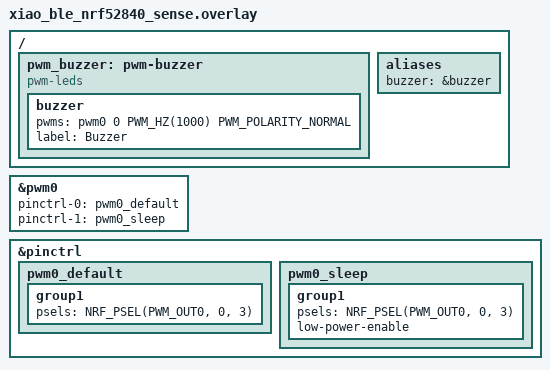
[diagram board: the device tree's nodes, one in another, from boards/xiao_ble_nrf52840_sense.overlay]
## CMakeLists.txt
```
# SPDX-License-Identifier: Apache-2.0

cmake_minimum_required(VERSION 3.20.0)
find_package(Zephyr REQUIRED HINTS $ENV{ZEPHYR_BASE})
project(project_base_node)

target_include_directories(app PRIVATE include)

target_sources(app PRIVATE src/main.c src/nus_central.c src/json_serial.c src/watchdog.c src/buzzer.c src/air_quality.c src/kalman.c src/node_buffer.c)
```

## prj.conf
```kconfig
CONFIG_SHELL=y
CONFIG_PRINTK=y
CONFIG_UART_CONSOLE=y

# Bluetooth core
CONFIG_BT=y
CONFIG_BT_CENTRAL=y
CONFIG_BT_GATT_CLIENT=y
CONFIG_BT_SMP=y
CONFIG_BT_MAX_CONN=1
CONFIG_BT_OBSERVER=y

# Data Length Extension and MTU
CONFIG_BT_USER_DATA_LEN_UPDATE=y
CONFIG_BT_CTLR_DATA_LENGTH_MAX=251
CONFIG_BT_BUF_ACL_RX_SIZE=251
CONFIG_BT_BUF_ACL_TX_SIZE=251
CONFIG_BT_L2CAP_TX_MTU=247

# Logging
CONFIG_LOG=y
CONFIG_LOG_DEFAULT_LEVEL=3

CONFIG_JSON_LIBRARY=y

CONFIG_WATCHDOG=y

CONFIG_PWM=y
CONFIG_PWM_LOG_LEVEL_DBG=y

CONFIG_FPU=y
CONFIG_FPU_SHARING=y
CONFIG_CBPRINTF_FP_SUPPORT=y
```

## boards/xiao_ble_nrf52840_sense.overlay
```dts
/ {
    pwm_buzzer: pwm-buzzer {
        compatible = "pwm-leds";
        buzzer: buzzer {
            pwms = <&pwm0 0 PWM_HZ(1000) PWM_POLARITY_NORMAL>;
            label = "Buzzer";
        };
    };

    aliases {
        buzzer = &buzzer;
    };
};

&pwm0 {
    status = "okay";
    pinctrl-0 = <&pwm0_default>;
    pinctrl-1 = <&pwm0_sleep>;
    pinctrl-names = "default", "sleep";
};

&pinctrl {
    pwm0_default: pwm0_default {
        group1 {
            psels = <NRF_PSEL(PWM_OUT0, 0, 3)>;
        };
    };

    pwm0_sleep: pwm0_sleep {
        group1 {
            psels = <NRF_PSEL(PWM_OUT0, 0, 3)>;
            low-power-enable;
        };
    };
};
```

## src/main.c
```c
#include <zephyr/kernel.h>
#include <zephyr/logging/log.h>
#include <zephyr/shell/shell.h>

#include "nus_central.h"
#include "watchdog.h"
#include "air_quality.h"
#include "buzzer.h"
#include "node_buffer.h"

LOG_MODULE_REGISTER(main, LOG_LEVEL_INF);

#define CMD_MEASURE 0x01
#define CMD_SLEEP   0x02

#define WDT_FEED_STACK  512
#define WDT_FEED_PERIOD_MS 2000  

K_THREAD_STACK_DEFINE(wdt_feed_stack, WDT_FEED_STACK);
static struct k_thread wdt_feed_thread_data;

static int cmd_wake(const struct shell *sh, size_t argc, char **argv)
{
    ARG_UNUSED(argc);
    ARG_UNUSED(argv);

    if (!nus_central_is_connected()) {
        shell_error(sh, "Not connected to mobile_node");
        return -ENOTCONN;
    }

    int err = nus_send_command(CMD_MEASURE);
    if (err) {
        shell_error(sh, "Failed to send CMD_MEASURE (err %d)", err);
        return err;
    }

    return 0;
}

static int cmd_sleep(const struct shell *sh, size_t argc, char **argv)
{
    ARG_UNUSED(argc);
    ARG_UNUSED(argv);

    if (!nus_central_is_connected()) {
        shell_error(sh, "Not connected to mobile_node");
        return -ENOTCONN;
    }

    int err = nus_send_command(CMD_SLEEP);
    if (err) {
        shell_error(sh, "Failed to send CMD_SLEEP (err %d)", err);
        return err;
    }

    shell_print(sh, "CMD_SLEEP sent to mobile_node");
    buzzer_stop();
    air_quality_reset();
    nus_central_reset_classification();

    return 0;
}

SHELL_CMD_REGISTER(wake,  NULL, "Send CMD_MEASURE to sensor mesh", cmd_wake);
SHELL_CMD_REGISTER(sleep, NULL, "Send CMD_SLEEP to sensor mesh",   cmd_sleep);

static void wdt_feed_thread(void *p1, void *p2, void *p3)
{
    ARG_UNUSED(p1);
    ARG_UNUSED(p2);
    ARG_UNUSED(p3);

    while (1) {
        watchdog_feed();
        k_sleep(K_MSEC(WDT_FEED_PERIOD_MS));
    }
}

int main(void)
{
    watchdog_init();

    k_thread_create(&wdt_feed_thread_data, wdt_feed_stack,
                    WDT_FEED_STACK,
                    wdt_feed_thread, NULL, NULL, NULL,
                    7, 0, K_NO_WAIT);
    k_thread_name_set(&wdt_feed_thread_data, "wdt_feed");

    node_buffer_init();
    air_quality_init();
    buzzer_init();

    int err = nus_central_init();
    if (err) {
        LOG_ERR("NUS central init failed (err %d)", err);
        return err;
    }

    return 0;
}
```

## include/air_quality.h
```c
#ifndef AIR_QUALITY_H
#define AIR_QUALITY_H

#include <stdint.h>

typedef enum {
    AQ_GOOD,
    AQ_WARNING,
    AQ_POOR
} air_quality_t;


void air_quality_init(void);
void air_quality_update(uint16_t eco2_ppm, uint16_t tvoc_ppb);
void air_quality_reset(void);
air_quality_t air_quality_get_eco2(void);
air_quality_t air_quality_get_tvoc(void);
float air_quality_get_eco2_estimate(void);
float air_quality_get_tvoc_estimate(void);

#endif /* AIR_QUALITY_H */
```

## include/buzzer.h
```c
#ifndef BUZZER_H
#define BUZZER_H

int buzzer_init(void);
void buzzer_warning(void);
void buzzer_poor(void);
void buzzer_stop(void);

#endif /* BUZZER_H */
```

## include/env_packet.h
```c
#ifndef ENV_PACKET_H
#define ENV_PACKET_H

#include <stdint.h>

#define ENV_NODE_NAME_LEN 8

struct env_record {
    char     node_id[ENV_NODE_NAME_LEN];  
    uint32_t timestamp_ms;                 
    int16_t  temp_centi_c;                 
    uint16_t hum_centi_rh;                
    uint16_t eco2_ppm;                     
    uint16_t tvoc_ppb;                     
};

#endif /* ENV_PACKET_H */
```

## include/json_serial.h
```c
#ifndef JSON_SERIAL_H
#define JSON_SERIAL_H

#include "env_packet.h"

void json_serial_send(const struct env_record *rec);
void json_serial_send_kalman(void);

#endif /* JSON_SERIAL_H */
```

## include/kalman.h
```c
#ifndef KALMAN_H
#define KALMAN_H

#include <stdint.h>

struct kalman_filter {
    float x; 
    float p;  
    float q;  
    float r; 
};

void kalman_init(struct kalman_filter *kf, float q, float r, float initial_x);
float kalman_update(struct kalman_filter *kf, float measurement);

#endif /* KALMAN_H */
```

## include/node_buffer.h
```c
#ifndef NODE_BUFFER_H
#define NODE_BUFFER_H

#include "env_packet.h"
#include <stdbool.h>

#define NODE_BUFFER_MAX 8

void node_buffer_init(void);
void node_buffer_add(const struct env_record *rec);
int node_buffer_count(void);
const struct env_record *node_buffer_get(int index);
void node_buffer_clear(void);

#endif /* NODE_BUFFER_H */
```

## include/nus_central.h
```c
#ifndef NUS_CENTRAL_H
#define NUS_CENTRAL_H

#include <stdint.h>
#include <stdbool.h>


int nus_central_init(void);
int nus_send_command(uint8_t cmd);
bool nus_central_is_connected(void);
// Resets air_quality classification
void nus_central_reset_classification(void);

#endif /* NUS_CENTRAL_H */
```

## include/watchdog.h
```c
#ifndef WATCHDOG_H
#define WATCHDOG_H

int watchdog_init(void);
void watchdog_feed(void);

#endif /* WATCHDOG_H */
```

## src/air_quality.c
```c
/*
 * Black-Valetudo - Base Node
 * Air quality classification using Kalman filter
 */

#include "air_quality.h"
#include "kalman.h"

#include <zephyr/kernel.h>
#include <zephyr/logging/log.h>

LOG_MODULE_REGISTER(air_quality, LOG_LEVEL_INF);

/* ==========================================================================
 * Kalman filter tuning parameters
 *
 * Q — process noise: how much we expect the true value to drift per update
 *     larger Q = trust measurements more, filter responds faster
 *
 * R — measurement noise: how noisy the sensor readings are
 *     larger R = trust measurements less, filter responds slower
 * ========================================================================== */

#define ECO2_Q          5.0f /* increased from 1.0f to 5.0f to track changes faster*/
#define ECO2_R          10.0f
#define ECO2_INITIAL    400.0f   /* typical outdoor CO2 level */

#define TVOC_Q          0.5f
#define TVOC_R          5.0f
#define TVOC_INITIAL    0.0f

#define ECO2_WARNING_PPM   1000
#define ECO2_POOR_PPM      2000

#define TVOC_WARNING_PPB   220
#define TVOC_POOR_PPB      660

/* Filter state */
static struct kalman_filter eco2_filter;
static struct kalman_filter tvoc_filter;

void air_quality_init(void)
{
    kalman_init(&eco2_filter, ECO2_Q, ECO2_R, ECO2_INITIAL);
    kalman_init(&tvoc_filter, TVOC_Q, TVOC_R, TVOC_INITIAL);

    LOG_INF("Air quality Kalman filters initialised");
}

void air_quality_update(uint16_t eco2_ppm, uint16_t tvoc_ppb)
{
    float eco2_est = kalman_update(&eco2_filter, (float)eco2_ppm);
    float tvoc_est = kalman_update(&tvoc_filter, (float)tvoc_ppb);

    LOG_INF("Kalman estimate — eCO2: %.1f ppm  TVOC: %.1f ppb",
            (double)eco2_est, (double)tvoc_est);
}

float air_quality_get_eco2_estimate(void)
{
    return eco2_filter.x;
}

float air_quality_get_tvoc_estimate(void)
{
    return tvoc_filter.x;
}

air_quality_t air_quality_get_eco2(void)
{
    float est = eco2_filter.x;

    if (est >= ECO2_POOR_PPM) {
        return AQ_POOR;
    } else if (est >= ECO2_WARNING_PPM) {
        return AQ_WARNING;
    }
    return AQ_GOOD;
}

air_quality_t air_quality_get_tvoc(void)
{
    float est = tvoc_filter.x;

    if (est >= TVOC_POOR_PPB) {
        return AQ_POOR;
    } else if (est >= TVOC_WARNING_PPB) {
        return AQ_WARNING;
    }
    return AQ_GOOD;
}

void air_quality_reset(void)
{
    kalman_init(&eco2_filter, ECO2_Q, ECO2_R, ECO2_INITIAL);
    kalman_init(&tvoc_filter, TVOC_Q, TVOC_R, TVOC_INITIAL);
    LOG_INF("Air quality filters reset");
}
```

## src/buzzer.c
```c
#include "buzzer.h"

#include <zephyr/kernel.h>
#include <zephyr/logging/log.h>
#include <zephyr/drivers/pwm.h>

LOG_MODULE_REGISTER(buzzer, LOG_LEVEL_INF);

#define WARNING_FREQ_HZ   1000
#define POOR_FREQ_HZ      2000
#define CHIRP_DURATION_MS 200
#define CHIRP_COUNT       3

static const struct pwm_dt_spec buzzer_pwm =
    PWM_DT_SPEC_GET(DT_ALIAS(buzzer));

#define BUZZER_THREAD_STACK 512
#define BUZZER_THREAD_PRIO  10

K_THREAD_STACK_DEFINE(buzzer_stack, BUZZER_THREAD_STACK);
static struct k_thread buzzer_thread_data;

typedef enum {
    BUZZER_IDLE,
    BUZZER_WARNING,
    BUZZER_POOR,
    BUZZER_STOP,
} buzzer_cmd_t;

K_MSGQ_DEFINE(buzzer_msgq, sizeof(buzzer_cmd_t), 4, 1);

static void buzzer_thread(void *p1, void *p2, void *p3)
{
    ARG_UNUSED(p1);
    ARG_UNUSED(p2);
    ARG_UNUSED(p3);

    buzzer_cmd_t cmd;
    bool poor_active = false;

    while (1) {
        k_msgq_get(&buzzer_msgq, &cmd, K_FOREVER);

        switch (cmd) {

        case BUZZER_WARNING:
            for (int i = 0; i < CHIRP_COUNT; i++) {
                // 50% duty cycle
                pwm_set_dt(&buzzer_pwm,
                           PWM_HZ(WARNING_FREQ_HZ),
                           PWM_HZ(WARNING_FREQ_HZ) / 2);
                k_sleep(K_MSEC(CHIRP_DURATION_MS));
                pwm_set_dt(&buzzer_pwm,
                           PWM_HZ(WARNING_FREQ_HZ), 0);
                k_sleep(K_MSEC(CHIRP_DURATION_MS));
            }
            break;

        case BUZZER_POOR:
            poor_active = true;
            pwm_set_dt(&buzzer_pwm,
                       PWM_HZ(POOR_FREQ_HZ),
                       PWM_HZ(POOR_FREQ_HZ) / 2);

            while (poor_active) {
                buzzer_cmd_t inner_cmd;
                if (k_msgq_get(&buzzer_msgq,
                               &inner_cmd, K_NO_WAIT) == 0) {
                    if (inner_cmd == BUZZER_STOP) {
                        poor_active = false;
                    }
                }
                k_sleep(K_MSEC(100));
            }

            pwm_set_dt(&buzzer_pwm, PWM_HZ(POOR_FREQ_HZ), 0);
            break;

        case BUZZER_STOP:
            pwm_set_dt(&buzzer_pwm, PWM_HZ(POOR_FREQ_HZ), 0);
            break;

        default:
            break;
        }
    }
}

int buzzer_init(void)
{
    if (!pwm_is_ready_dt(&buzzer_pwm)) {
        LOG_ERR("Buzzer PWM not ready");
        return -ENODEV;
    }

    k_thread_create(&buzzer_thread_data, buzzer_stack,
                    BUZZER_THREAD_STACK,
                    buzzer_thread, NULL, NULL, NULL,
                    BUZZER_THREAD_PRIO, 0, K_NO_WAIT);
    k_thread_name_set(&buzzer_thread_data, "buzzer");

    LOG_INF("Buzzer initialised");
    return 0;
}

void buzzer_warning(void)
{
    buzzer_cmd_t cmd = BUZZER_WARNING;
    k_msgq_put(&buzzer_msgq, &cmd, K_NO_WAIT);
}

void buzzer_poor(void)
{
    buzzer_cmd_t cmd = BUZZER_POOR;
    k_msgq_put(&buzzer_msgq, &cmd, K_NO_WAIT);
}

void buzzer_stop(void)
{
    buzzer_cmd_t cmd = BUZZER_STOP;
    k_msgq_put(&buzzer_msgq, &cmd, K_NO_WAIT);
}
```

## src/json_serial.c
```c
#include "json_serial.h"
#include "air_quality.h"

#include <zephyr/kernel.h>
#include <zephyr/logging/log.h>
#include <zephyr/data/json.h>

LOG_MODULE_REGISTER(json_serial, LOG_LEVEL_INF);

struct node_record_json {
    const char *type;
    const char *node_id;
    uint32_t    timestamp_ms;
    int32_t     temperature;
    uint32_t    humidity;
    uint32_t    eco2;
    uint32_t    tvoc;
};

static const struct json_obj_descr node_record_descr[] = {
    JSON_OBJ_DESCR_PRIM(struct node_record_json, type,         JSON_TOK_STRING),
    JSON_OBJ_DESCR_PRIM(struct node_record_json, node_id,      JSON_TOK_STRING),
    JSON_OBJ_DESCR_PRIM(struct node_record_json, timestamp_ms, JSON_TOK_NUMBER),
    JSON_OBJ_DESCR_PRIM(struct node_record_json, temperature,  JSON_TOK_NUMBER),
    JSON_OBJ_DESCR_PRIM(struct node_record_json, humidity,     JSON_TOK_NUMBER),
    JSON_OBJ_DESCR_PRIM(struct node_record_json, eco2,         JSON_TOK_NUMBER),
    JSON_OBJ_DESCR_PRIM(struct node_record_json, tvoc,         JSON_TOK_NUMBER),
};

struct kalman_json {
    const char *type;
    uint32_t    timestamp_ms;
    int32_t     eco2_estimate;
    int32_t     tvoc_estimate;
    const char *eco2_class;
    const char *tvoc_class;
};

static const struct json_obj_descr kalman_descr[] = {
    JSON_OBJ_DESCR_PRIM(struct kalman_json, type,          JSON_TOK_STRING),
    JSON_OBJ_DESCR_PRIM(struct kalman_json, timestamp_ms,  JSON_TOK_NUMBER),
    JSON_OBJ_DESCR_PRIM(struct kalman_json, eco2_estimate, JSON_TOK_NUMBER),
    JSON_OBJ_DESCR_PRIM(struct kalman_json, tvoc_estimate, JSON_TOK_NUMBER),
    JSON_OBJ_DESCR_PRIM(struct kalman_json, eco2_class,    JSON_TOK_STRING),
    JSON_OBJ_DESCR_PRIM(struct kalman_json, tvoc_class,    JSON_TOK_STRING),
};

static const char *class_to_str(air_quality_t cls)
{
    switch (cls) {
    case AQ_POOR:    return "poor";
    case AQ_WARNING: return "warning";
    default:         return "good";
    }
}

void json_serial_send(const struct env_record *rec)
{
    struct node_record_json json_rec = {
        .type         = "node",
        .node_id      = rec->node_id,
        .timestamp_ms = rec->timestamp_ms,
        .temperature  = rec->temp_centi_c,
        .humidity     = rec->hum_centi_rh,
        .eco2         = rec->eco2_ppm,
        .tvoc         = rec->tvoc_ppb,
    };

    char buf[256];
    int ret = json_obj_encode_buf(node_record_descr,
                                  ARRAY_SIZE(node_record_descr),
                                  &json_rec, buf, sizeof(buf));
    if (ret < 0) {
        LOG_ERR("Node JSON encode failed (err %d)", ret);
        return;
    }

    printk("%s\n", buf);
}

void json_serial_send_kalman(void)
{
    struct kalman_json json_kal = {
        .type          = "kalman",
        .timestamp_ms  = (uint32_t)k_uptime_get(),
        .eco2_estimate = (int32_t)air_quality_get_eco2_estimate(),
        .tvoc_estimate = (int32_t)air_quality_get_tvoc_estimate(),
        .eco2_class    = class_to_str(air_quality_get_eco2()),
        .tvoc_class    = class_to_str(air_quality_get_tvoc()),
    };

    char buf[256];
    int ret = json_obj_encode_buf(kalman_descr,
                                  ARRAY_SIZE(kalman_descr),
                                  &json_kal, buf, sizeof(buf));
    if (ret < 0) {
        LOG_ERR("Kalman JSON encode failed (err %d)", ret);
        return;
    }

    printk("%s\n", buf);
}
```

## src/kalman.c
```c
#include "kalman.h"
#include <zephyr/logging/log.h>

LOG_MODULE_REGISTER(kalman, LOG_LEVEL_INF);

void kalman_init(struct kalman_filter *kf, float q, float r, float initial_x)
{
    // State estimate
    kf->x = initial_x;
    // error covariance, it is the uncertainty in the current state estimation.
    // It shrinks when measurements confirms state estimation
    kf->p = 1.0f;
    kf->q = q;
    kf->r = r;
}

float kalman_update(struct kalman_filter *kf, float measurement)
{
    /* Predict */
    kf->p = kf->p + kf->q;

    /* Update */

    /* Kalman gain. If gain is 1, trust measurement more */
    float k = kf->p / (kf->p + kf->r);
    kf->x = kf->x + k * (measurement - kf->x);
    kf->p = (1.0f - k) * kf->p;

    return kf->x;
}
```
